# CH573SFR register map
Vendor: WCH Ltd.; Series: CH57x; File version: 1.0
CPU: RISC-V r0p0, little endian, no MPU, no FPU, 2 interrupt priority bits
Registers are 8-bit, read-write, reset 0x0 unless marked. A register's access mark holds for its fields unless they carry their own. Offsets are from the block's base; [hi:lo] are bit positions; {n}, {i} and the like mark numbered series.

## PFIC — Program Fast Interrupt Controller
Base 0xE000E000
0x00 R32_PFIC_ISR1 32-bit access not given — RO,Interrupt Status Register
  [31:12] INTENSTA — Interrupt ID Status
0x04 R32_PFIC_ISR2 32-bit access not given — RO,Interrupt Status Register
  [3:0] INTENSTA — Interrupt ID Status
0x20 R32_PFIC_IPR1 32-bit access not given — RO,Interrupt Pending Register
  [31:12] PENDSTA
0x24 R32_PFIC_IPR2 32-bit ro — RO,Interrupt Pending Register
  [3:0] PENDSTA
0x40 R32_PFIC_ITHRESDR 32-bit — RW,Interrupt Priority Register
  [7:0] THRESHOLD — RW,THRESHOLD
0x44 R32_PFIC_FIBADDRR 32-bit — RW,Interrupt Fast Address Register
  [31:28] BASEADDR
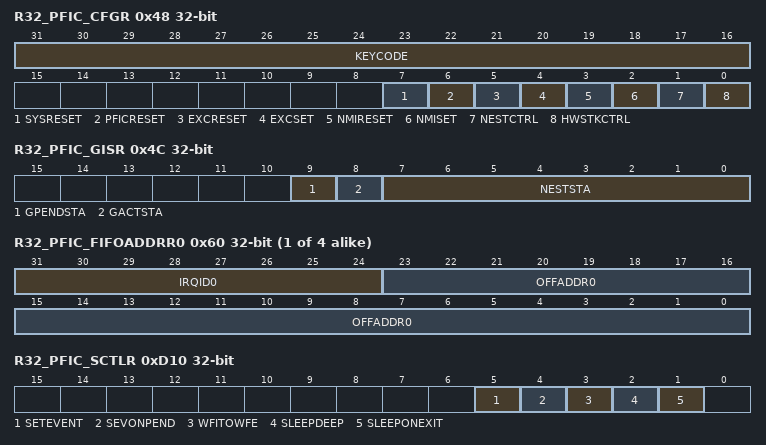
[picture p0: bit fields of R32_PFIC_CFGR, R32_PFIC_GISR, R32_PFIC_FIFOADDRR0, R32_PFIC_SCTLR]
0x48 R32_PFIC_CFGR 32-bit — Interrupt Config Register
  [31:16] KEYCODE — WO,KEYCODE
  [7] SYSRESET — WO,SYSRESET
  [6] PFICRESET — WO,PFICRSET
  [5] EXCRESET — WO,EXCRESET
  [4] EXCSET — WO,EXCSET
  [3] NMIRESET — WO,NMIRESET
  [2] NMISET — WO,NMISET
  [1] NESTCTRL — RW,NESTCTRL
  [0] HWSTKCTRL — RW,HWSTKCTRL
0x4C R32_PFIC_GISR 32-bit ro — Interrupt Global Register
  [9] GPENDSTA — RO,GPENDSTA
  [8] GACTSTA — RO,GACTSTA
  [7:0] NESTSTA — RO,NESTSTA
{0x60+4i} R32_PFIC_FIFOADDRR{i} 32-bit (i=0..3) — Interrupt {i} address Register
  [31:24] IRQID{i} — RW,IRQID{i}
  [23:0] OFFADDR{i} — RW,OFFADDR{i}
0x100 R32_PFIC_IENR1 32-bit — Interrupt Setting Register
  [31:12] INTEN — RW1,INTEN
0x104 R32_PFIC_IENR2 32-bit — Interrupt Setting Register
  [3:0] INTEN — RW1,INTEN
0x180 R32_PFIC_IRER1 32-bit — Interrupt Clear Register
  [31:12] INTRESET — RW1,INTRESET
0x184 R32_PFIC_IRER2 32-bit — Interrupt Clear Register
  [3:0] INTRESET — RW1,INTRESET
0x200 R32_PFIC_IPSR1 32-bit — Interrupt Pending Register
  [31:12] PENDSET — RW1,PENDSET
0x204 R32_PFIC_IPSR2 32-bit — Interrupt Pending Register
  [3:0] PENDSET — RW1,PENDSET
0x280 R32_PFIC_IPRR1 32-bit — Interrupt Pending Clear Register
  [31:12] PENDRESET — RW1,PENDRESET
0x284 R32_PFIC_IPRR2 32-bit — Interrupt Pending Clear Register
  [3:0] PENDRESET — RW1,PENDRESET
0x300 R32_PFIC_IACTR1 32-bit — Interrupt ACTIVE Register
  [31:12] IACTS — RW1,IACTS
0x304 R32_PFIC_IACTR2 32-bit — Interrupt ACTIVE Register
  [3:0] IACTS — RW1,IACTS
0x400 R32_PFIC_IPRIOR0 32-bit — Interrupt Priority configuration Register
  [31:0] IPRIOR0 — RW,IPRIOR0
{0x400+0x20*i} R32_PFIC_IPRIOR{i} 32-bit (i=1..10) — Interrupt Priority configuration Register
  [31:0] IPRIOR{i} — >RW,IPRIOR{i}
{0x400+0x20*i} R32_PFIC_IPRIOR{i} 32-bit (i=11..53) — Interrupt Priority configuration Register
  [31:0] IPRIOR{i} — RW,IPRIOR{i}
0xAD0 R32_PFIC_IPRIOR54 32-bit — Interrupt Priority configuration Register
  [31:0] IPRIOR54 — RW,IPRIOR54
{0x400+0x20*i} R32_PFIC_IPRIOR{i} 32-bit (i=55..61) — Interrupt Priority configuration Register
  [31:0] IPRIOR{i} — RW,IPRIOR{i}
0xBE0 R32_PFIC_IPRIOR62 32-bit — Interrupt Priority configuration Register
  [31:0] IPRIOR62 — RW,IPRIOR62
0xC00 R32_PFIC_IPRIOR63 32-bit — Interrupt Priority configuration Register
  [31:0] IPRIOR63 — RW,IPRIOR63
0xD10 R32_PFIC_SCTLR 32-bit — System Control Register
  [5] SETEVENT — WO,SETEVENT
  [4] SEVONPEND — RW,SEVONPEND
  [3] WFITOWFE — RW,WFITOWFE
  [2] SLEEPDEEP — RW,SLEEPDEEP
  [1] SLEEPONEXIT — RW,SLEEPONEXIT
0xD14 R32_PFIC_VTCTLR 32-bit — System Control Register
  [0] VTADDR

## Systick
Base 0xE000F000
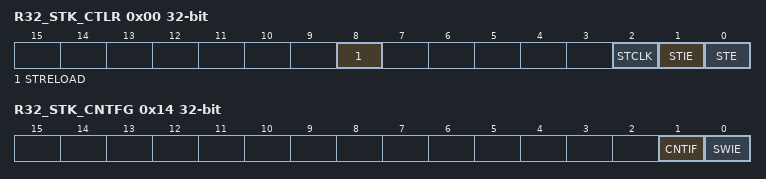
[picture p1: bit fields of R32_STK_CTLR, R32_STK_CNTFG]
0x00 R32_STK_CTLR 32-bit — Systick counter control register
  [8] STRELOAD — System counter reload control
  [2] STCLK — System counter clock Source selection
  [1] STIE — Systick counter interrupt enable
  [0] STE — Systick counter enable
0x04 R32_STK_CNTL 32-bit — Systick counter low register
  [31:0] CNTL — RW,CNTL
0x08 R32_STK_CNTH 32-bit — Systick counter high register
  [31:0] CNTH — RW,CNTH
0x0C R32_STK_CMPLR 32-bit — Systick compare low register
  [31:0] CMPL — RW,CMPL
0x10 R32_STK_CMPHR 32-bit — Systick compare high register
  [31:0] CMPH — RW,CMPH
0x14 R32_STK_CNTFG 32-bit — Systick counter flag
  [1] CNTIF — RW,Systick counter clear zero flag
  [0] SWIE — RW0,System soft interrupt enable
